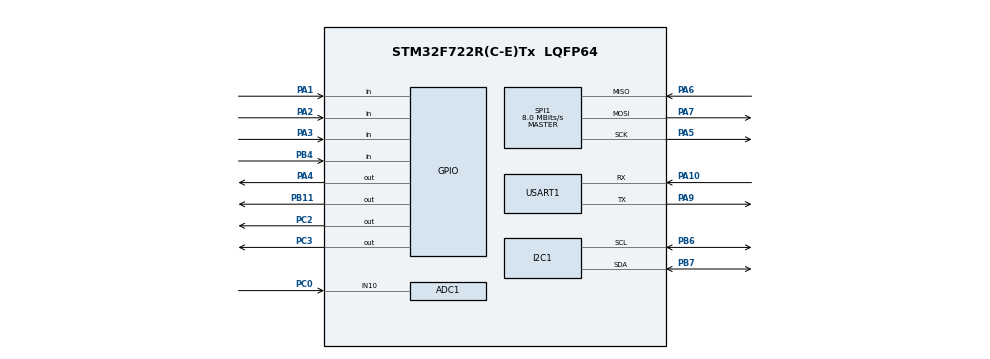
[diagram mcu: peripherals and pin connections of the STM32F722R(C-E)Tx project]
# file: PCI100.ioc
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ADC1.Channel-1\#ChannelRegularConversion=ADC_CHANNEL_10
ADC1.NbrOfConversionFlag=1
ADC1.Rank-1\#ChannelRegularConversion=1
ADC1.SamplingTime-1\#ChannelRegularConversion=ADC_SAMPLETIME_3CYCLES
ADC1.master=1
CORTEX_M7.default_mode_Activation=1
Dma.Request0=USART1_RX
Dma.Request1=USART1_TX
Dma.USART1_RX.0.Direction=DMA_PERIPH_TO_MEMORY
Dma.USART1_RX.0.FIFOMode=DMA_FIFOMODE_ENABLE
Dma.USART1_RX.0.FIFOThreshold=DMA_FIFO_THRESHOLD_FULL
Dma.USART1_RX.0.Instance=DMA2_Stream2
Dma.USART1_RX.0.MemBurst=DMA_MBURST_SINGLE
Dma.USART1_RX.0.MemDataAlignment=DMA_MDATAALIGN_BYTE
Dma.USART1_RX.0.MemInc=DMA_MINC_ENABLE
Dma.USART1_RX.0.Mode=DMA_NORMAL
Dma.USART1_RX.0.PeriphBurst=DMA_PBURST_SINGLE
Dma.USART1_RX.0.PeriphDataAlignment=DMA_PDATAALIGN_BYTE
Dma.USART1_RX.0.PeriphInc=DMA_PINC_DISABLE
Dma.USART1_RX.0.Priority=DMA_PRIORITY_LOW
Dma.USART1_TX.1.Direction=DMA_MEMORY_TO_PERIPH
Dma.USART1_TX.1.FIFOMode=DMA_FIFOMODE_DISABLE
Dma.USART1_TX.1.Instance=DMA2_Stream7
Dma.USART1_TX.1.MemDataAlignment=DMA_MDATAALIGN_BYTE
Dma.USART1_TX.1.MemInc=DMA_MINC_ENABLE
Dma.USART1_TX.1.Mode=DMA_NORMAL
Dma.USART1_TX.1.PeriphDataAlignment=DMA_PDATAALIGN_BYTE
Dma.USART1_TX.1.PeriphInc=DMA_PINC_DISABLE
Dma.USART1_TX.1.Priority=DMA_PRIORITY_LOW
Mcu.Family=STM32F7
Mcu.Name=STM32F722R(C-E)Tx
Mcu.Package=LQFP64
NVIC.ADC_IRQn=true\:0\:0\:false\:false\:true\:true\:true\:true
NVIC.DMA2_Stream2_IRQn=true\:0\:0\:false\:false\:true\:false\:true\:true
NVIC.DMA2_Stream7_IRQn=true\:0\:0\:false\:false\:true\:false\:true\:true
NVIC.I2C1_ER_IRQn=true\:0\:0\:false\:false\:true\:true\:true\:true
NVIC.I2C1_EV_IRQn=true\:0\:0\:false\:false\:true\:true\:true\:true
NVIC.PriorityGroup=NVIC_PRIORITYGROUP_4
NVIC.SPI1_IRQn=true\:0\:0\:false\:false\:true\:true\:true\:true
NVIC.USART1_IRQn=true\:0\:0\:false\:false\:true\:true\:true\:true
PA0-WKUP.Mode=SYS_WakeUp0
PA0-WKUP.Signal=SYS_WKUP1
PA1.GPIO_PuPd=GPIO_PULLUP
PA1.Signal=GPIO_Input
PA10.Mode=Asynchronous
PA10.Signal=USART1_RX
PA13.Mode=Trace_Asynchronous_SW
PA13.Signal=SYS_JTMS-SWDIO
PA14.Mode=Trace_Asynchronous_SW
PA14.Signal=SYS_JTCK-SWCLK
PA2.GPIO_PuPd=GPIO_PULLUP
PA2.Signal=GPIO_Input
PA3.GPIO_PuPd=GPIO_PULLUP
PA3.Signal=GPIO_Input
PA4.GPIO_PuPd=GPIO_PULLUP
PA4.Signal=GPIO_Output
PA5.GPIO_PuPd=GPIO_PULLUP
PA5.Mode=Full_Duplex_Master
PA5.Signal=SPI1_SCK
PA6.GPIO_PuPd=GPIO_PULLUP
PA6.Mode=Full_Duplex_Master
PA6.Signal=SPI1_MISO
PA7.GPIO_PuPd=GPIO_PULLUP
PA7.Mode=Full_Duplex_Master
PA7.Signal=SPI1_MOSI
PA9.Mode=Asynchronous
PA9.Signal=USART1_TX
PB11.GPIO_PuPd=GPIO_PULLUP
PB11.Signal=GPIO_Output
PB3.Mode=Trace_Asynchronous_SW
PB3.Signal=SYS_JTDO-SWO
PB4.GPIO_PuPd=GPIO_PULLUP
PB4.Signal=GPIO_Input
PB6.Mode=I2C
PB6.Signal=I2C1_SCL
PB7.Mode=I2C
PB7.Signal=I2C1_SDA
PC0.Signal=ADCx_IN10
PC2.GPIO_PuPd=GPIO_PULLUP
PC2.Signal=GPIO_Output
PC3.GPIO_ModeDefaultOutputPP=GPIO_MODE_OUTPUT_OD
PC3.GPIO_PuPd=GPIO_PULLUP
PC3.Signal=GPIO_Output
PH0-OSC_IN.Mode=HSE-External-Oscillator
PH0-OSC_IN.Signal=RCC_OSC_IN
PH1-OSC_OUT.Mode=HSE-External-Oscillator
PH1-OSC_OUT.Signal=RCC_OSC_OUT
ProjectManager.HeapSize=0x200
ProjectManager.StackSize=0x400
ProjectManager.TargetToolchain=STM32CubeIDE
RCC.HSE_VALUE=25000000
RCC.HSI_VALUE=16000000
RCC.LSE_VALUE=32768
RCC.USBFreq_Value=96000000
RCC.VCOOutputFreq_Value=192000000
SH.ADCx_IN10.0=ADC1_IN10,IN10
SPI1.CalculateBaudRate=8.0 MBits/s
SPI1.DataSize=SPI_DATASIZE_8BIT
SPI1.Direction=SPI_DIRECTION_2LINES
SPI1.Mode=SPI_MODE_MASTER
SPI1.VirtualType=VM_MASTER
USART1.VirtualMode-Asynchronous=VM_ASYNC
board=custom

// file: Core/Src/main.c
/* USER CODE BEGIN Header */
/**
  ******************************************************************************
  * @file           : main.c
  * @brief          : Main program body
  ******************************************************************************
  * @attention
  *
  * Copyright (c) 2025 STMicroelectronics.
  * All rights reserved.
  *
  * This software is licensed under terms that can be found in the LICENSE file
  * in the root directory of this software component.
  * If no LICENSE file comes with this software, it is provided AS-IS.
  *
  ******************************************************************************
  */
/* USER CODE END Header */
#include "main.h"

DMA_HandleTypeDef hdma_usart1_rx;
DMA_HandleTypeDef hdma_usart1_tx;

/* USER CODE BEGIN PV */

extern UART_HandleTypeDef huart1;

/* USER CODE END PV */

static void MX_DMA_Init(void);

/* USER CODE BEGIN 0 */
extern uint8_t ch;
/* USER CODE END 0 */

int main(void)
{

  /* MPU Configuration--------------------------------------------------------*/
  MPU_Config();

  /* MCU Configuration--------------------------------------------------------*/

  /* Reset of all peripherals, Initializes the Flash interface and the Systick. */
  HAL_Init();

  /* Configure the system clock */
  SystemClock_Config();

  /* Initialize all configured peripherals */
  MX_GPIO_Init();
  MX_DMA_Init();
  MX_I2C1_Init();
  MX_USART1_UART_Init();
  MX_ADC1_Init();
  MX_SPI1_Init();
  /* USER CODE BEGIN 2 */

  HAL_UART_Receive_DMA(&huart1, &ch, 1);
  /* USER CODE END 2 */

  /* Infinite loop */
  /* USER CODE BEGIN WHILE */
  printf("\r\n%s", CLI_PROMPT);
  fflush(stdout);
  HAL_GPIO_WritePin(GPIOA, GPIO_PIN_4, GPIO_PIN_SET);
  while (1)
  {

		UART_To_CLI_Handler();
		Blink_Led();

    /* USER CODE END WHILE */

  }
}

static void MX_DMA_Init(void)
{

  /* DMA controller clock enable */
  __HAL_RCC_DMA2_CLK_ENABLE();

  /* DMA interrupt init */
  /* DMA2_Stream2_IRQn interrupt configuration */
  HAL_NVIC_SetPriority(DMA2_Stream2_IRQn, 0, 0);
  HAL_NVIC_EnableIRQ(DMA2_Stream2_IRQn);
  /* DMA2_Stream7_IRQn interrupt configuration */
  HAL_NVIC_SetPriority(DMA2_Stream7_IRQn, 0, 0);
  HAL_NVIC_EnableIRQ(DMA2_Stream7_IRQn);

}
